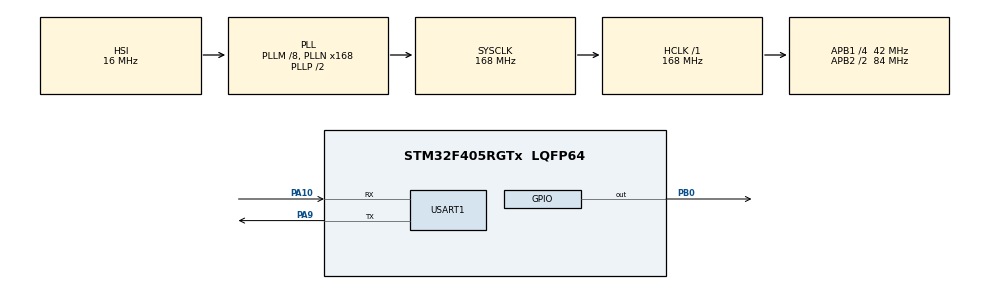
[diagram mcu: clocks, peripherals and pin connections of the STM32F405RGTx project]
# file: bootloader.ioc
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Mcu.Family=STM32F4
Mcu.Name=STM32F405RGTx
Mcu.Package=LQFP64
NVIC.PriorityGroup=NVIC_PRIORITYGROUP_4
PA10.Mode=Asynchronous
PA10.Signal=USART1_RX
PA13.Mode=Serial_Wire
PA13.Signal=SYS_JTMS-SWDIO
PA14.Mode=Serial_Wire
PA14.Signal=SYS_JTCK-SWCLK
PA9.Mode=Asynchronous
PA9.Signal=USART1_TX
PB0.Signal=GPIO_Output
PH0-OSC_IN.Mode=HSE-External-Oscillator
PH0-OSC_IN.Signal=RCC_OSC_IN
PH1-OSC_OUT.Mode=HSE-External-Oscillator
PH1-OSC_OUT.Signal=RCC_OSC_OUT
ProjectManager.HeapSize=0x200
ProjectManager.StackSize=0x400
ProjectManager.TargetToolchain=STM32CubeIDE
RCC.48MHZClocksFreq_Value=84000000
RCC.AHBFreq_Value=168000000
RCC.APB1CLKDivider=RCC_HCLK_DIV4
RCC.APB1Freq_Value=42000000
RCC.APB1TimFreq_Value=84000000
RCC.APB2CLKDivider=RCC_HCLK_DIV2
RCC.APB2Freq_Value=84000000
RCC.APB2TimFreq_Value=168000000
RCC.CortexFreq_Value=168000000
RCC.HCLKFreq_Value=168000000
RCC.HSE_VALUE=8000000
RCC.HSI_VALUE=16000000
RCC.LSE_VALUE=32768
RCC.PLLM=8
RCC.PLLN=168
RCC.SYSCLKFreq_VALUE=168000000
RCC.SYSCLKSource=RCC_SYSCLKSOURCE_PLLCLK
RCC.VCOOutputFreq_Value=336000000
USART1.VirtualMode=VM_ASYNC
board=custom

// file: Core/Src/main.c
/* USER CODE BEGIN Header */
/**
  ******************************************************************************
  * @file           : main.c of BOOTLOADER
  * @brief          : Main program body
  ******************************************************************************
  * @attention
  *
  * Copyright (c) 2022 STMicroelectronics.
  * All rights reserved.
  *
  * This software is licensed under terms that can be found in the LICENSE file
  * in the root directory of this software component.
  * If no LICENSE file comes with this software, it is provided AS-IS.
  *
  ******************************************************************************
  */
/* USER CODE END Header */
#include "main.h"

/* USER CODE BEGIN Includes */
#include <stdio.h>
/* USER CODE END Includes */

/* USER CODE BEGIN PTD */
typedef void (*pFunciton)();
/* USER CODE END PTD */

/* USER CODE BEGIN PD */
#define FLASH_APP_ADDR 0x8008000
/* USER CODE END PD */

UART_HandleTypeDef huart1;

void SystemClock_Config(void);
static void MX_GPIO_Init(void);
static void MX_USART1_UART_Init(void);
/* USER CODE BEGIN PFP */
void go2APP();
#ifdef __GNUC__
/* With GCC/RAISONANCE, small printf (option LD Linker->Libraries->Small printf
 set to 'Yes') calls __io_putchar() */
#define PUTCHAR_PROTOTYPE int __io_putchar(int ch)
#else
 #define PUTCHAR_PROTOTYPE int fputc(int ch, FILE *f)
#endif /* __GNUC__ */
/* USER CODE END PFP */

/* USER CODE BEGIN 0 */
//void __attribute__((section(".RamFunc"))) blink(uint32_t ticks) {
//	HAL_GPIO_TogglePin(GPIOB, GPIO_PIN_0);
//	HAL_Delay(ticks);
//}

void go2APP() {
	uint32_t jumpAddress;
	pFunciton jumpToApp;
	printf("Bootloader start!\r\n");

	//check if app is installed in flash region
	if (((*(uint32_t*) FLASH_APP_ADDR) & 0x2ffe0000) == 0x20020000) {
		printf("Jump to app!\r\n");
		HAL_Delay(1000);

		//jump to the app
		jumpAddress = *(uint32_t*) (FLASH_APP_ADDR+4);
		jumpToApp = (pFunciton) jumpAddress;

		//initial app stack pointer
		__set_MSP(*(uint32_t*)FLASH_APP_ADDR);
		jumpToApp();
	}
	else {
		printf("App not found!\r\n");
		HAL_GPIO_TogglePin(GPIOB, GPIO_PIN_0);
	}
}
/* USER CODE END 0 */

int main(void)
{

  /* MCU Configuration--------------------------------------------------------*/

  /* Reset of all peripherals, Initializes the Flash interface and the Systick. */
  HAL_Init();

  /* Configure the system clock */
  SystemClock_Config();

  /* Initialize all configured peripherals */
  MX_GPIO_Init();
  MX_USART1_UART_Init();

  /* Infinite loop */
  /* USER CODE BEGIN WHILE */
  while (1)
  {
	  go2APP();
    /* USER CODE END WHILE */

  }
}

void SystemClock_Config(void)
{
  RCC_OscInitTypeDef RCC_OscInitStruct = {0};
  RCC_ClkInitTypeDef RCC_ClkInitStruct = {0};

  /** Configure the main internal regulator output voltage
  */
  __HAL_RCC_PWR_CLK_ENABLE();
  __HAL_PWR_VOLTAGESCALING_CONFIG(PWR_REGULATOR_VOLTAGE_SCALE1);

  /** Initializes the RCC Oscillators according to the specified parameters
  * in the RCC_OscInitTypeDef structure.
  */
  RCC_OscInitStruct.OscillatorType = RCC_OSCILLATORTYPE_HSI;
  RCC_OscInitStruct.HSIState = RCC_HSI_ON;
  RCC_OscInitStruct.HSICalibrationValue = RCC_HSICALIBRATION_DEFAULT;
  RCC_OscInitStruct.PLL.PLLState = RCC_PLL_ON;
  RCC_OscInitStruct.PLL.PLLSource = RCC_PLLSOURCE_HSI;
  RCC_OscInitStruct.PLL.PLLM = 8;
  RCC_OscInitStruct.PLL.PLLN = 168;
  RCC_OscInitStruct.PLL.PLLP = RCC_PLLP_DIV2;
  RCC_OscInitStruct.PLL.PLLQ = 4;
  if (HAL_RCC_OscConfig(&RCC_OscInitStruct) != HAL_OK)
  {
    Error_Handler();
  }

  /** Initializes the CPU, AHB and APB buses clocks
  */
  RCC_ClkInitStruct.ClockType = RCC_CLOCKTYPE_HCLK|RCC_CLOCKTYPE_SYSCLK
                              |RCC_CLOCKTYPE_PCLK1|RCC_CLOCKTYPE_PCLK2;
  RCC_ClkInitStruct.SYSCLKSource = RCC_SYSCLKSOURCE_PLLCLK;
  RCC_ClkInitStruct.AHBCLKDivider = RCC_SYSCLK_DIV1;
  RCC_ClkInitStruct.APB1CLKDivider = RCC_HCLK_DIV4;
  RCC_ClkInitStruct.APB2CLKDivider = RCC_HCLK_DIV2;

  if (HAL_RCC_ClockConfig(&RCC_ClkInitStruct, FLASH_LATENCY_5) != HAL_OK)
  {
    Error_Handler();
  }
}

static void MX_USART1_UART_Init(void)
{

  huart1.Instance = USART1;
  huart1.Init.BaudRate = 115200;
  huart1.Init.WordLength = UART_WORDLENGTH_8B;
  huart1.Init.StopBits = UART_STOPBITS_1;
  huart1.Init.Parity = UART_PARITY_NONE;
  huart1.Init.Mode = UART_MODE_TX_RX;
  huart1.Init.HwFlowCtl = UART_HWCONTROL_NONE;
  huart1.Init.OverSampling = UART_OVERSAMPLING_16;
  if (HAL_UART_Init(&huart1) != HAL_OK)
  {
    Error_Handler();
  }

}

static void MX_GPIO_Init(void)
{
  GPIO_InitTypeDef GPIO_InitStruct = {0};

  /* GPIO Ports Clock Enable */
  __HAL_RCC_GPIOH_CLK_ENABLE();
  __HAL_RCC_GPIOB_CLK_ENABLE();
  __HAL_RCC_GPIOA_CLK_ENABLE();

  /*Configure GPIO pin Output Level */
  HAL_GPIO_WritePin(GPIOB, GPIO_PIN_0, GPIO_PIN_RESET);

  /*Configure GPIO pin : PB0 */
  GPIO_InitStruct.Pin = GPIO_PIN_0;
  GPIO_InitStruct.Mode = GPIO_MODE_OUTPUT_PP;
  GPIO_InitStruct.Pull = GPIO_NOPULL;
  GPIO_InitStruct.Speed = GPIO_SPEED_FREQ_LOW;
  HAL_GPIO_Init(GPIOB, &GPIO_InitStruct);

}

/* USER CODE BEGIN 4 */
/**
 * @brief Retargets the C library printf function to the USART.
 * @param None
 * @retval None
 */
PUTCHAR_PROTOTYPE
{
  /* Place your implementation of fputc here */
  /* e.g. write a character to the USART */
  HAL_UART_Transmit(&huart1, (uint8_t*) &ch, 1, 100);
  return ch;
}
/* USER CODE END 4 */

void Error_Handler(void)
{
  __disable_irq();
  while (1)
  {
  }
}
